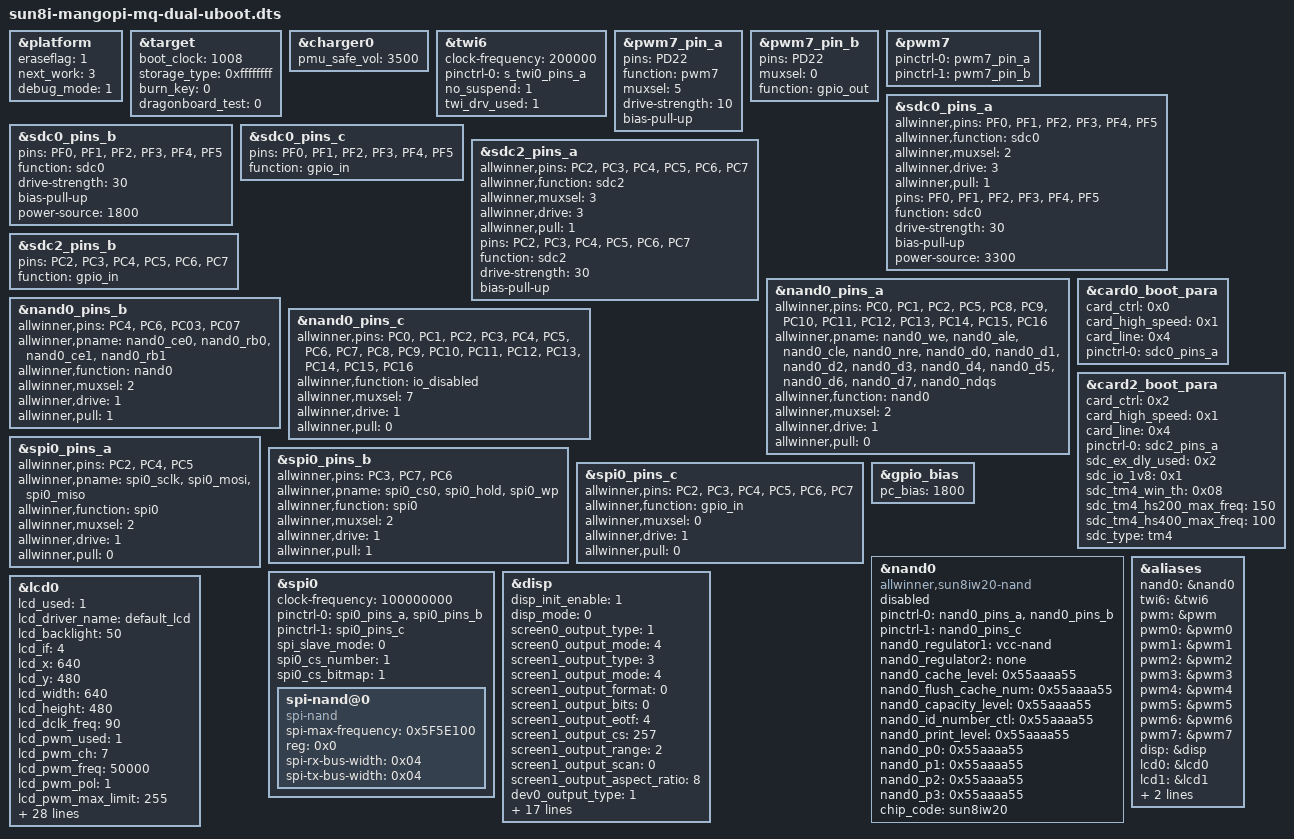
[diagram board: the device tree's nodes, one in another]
/*
 * Allwinner Technology CO., Ltd. sun8iw20p1 soc board.
 *
 * soc board support.
 */
/dts-v1/;

#include "sun8iw20p1-soc-system.dtsi"

&platform {
	eraseflag   = <1>;
	next_work   = <3>;
	debug_mode  = <1>;
};

&target {
	boot_clock = <1008>;	/*CPU boot frequency, Unit: MHz*/
	storage_type = <0xffffffff>; /*boot medium, 0-nand, 1-card0, 2-card2, -1(defualt)auto scan*/
	burn_key = <0>;		/*1:support burn key; 0:not support burn key*/
	dragonboard_test = <0>;	/*1:support card boot dragonboard; 0:not support card boot dragonboard*/
};

&charger0 {
	pmu_safe_vol = <3500>;
};

&twi6 {
	clock-frequency = <200000>;
	pinctrl-0 = <&s_twi0_pins_a>;
	no_suspend = <1>;
	twi_drv_used = <1>;
	status = "okay";
};

&pwm7_pin_a {
	pins = "PD22";
	function = "pwm7";
	muxsel = <5>;
	drive-strength = <10>;
	bias-pull-up;
};

&pwm7_pin_b {
	pins = "PD22";
	muxsel = <0>;
	function = "gpio_out";
};

&pwm7 {
	pinctrl-names = "active", "sleep";
	pinctrl-0 = <&pwm7_pin_a>;
	pinctrl-1 = <&pwm7_pin_b>;
	status = "okay";
};

&sdc0_pins_a {
	allwinner,pins = "PF0", "PF1", "PF2",
			 "PF3", "PF4", "PF5";
	allwinner,function = "sdc0";
	allwinner,muxsel = <2>;
	allwinner,drive = <3>;
	allwinner,pull = <1>;
	pins = "PF0", "PF1", "PF2",
	       "PF3", "PF4", "PF5";
	function = "sdc0";
	drive-strength = <30>;
	bias-pull-up;
	power-source = <3300>;
};

&sdc0_pins_b {
	pins = "PF0", "PF1", "PF2",
	       "PF3", "PF4", "PF5";
	function = "sdc0";
	drive-strength = <30>;
	bias-pull-up;
	power-source = <1800>;
};

&sdc0_pins_c {
		pins = "PF0", "PF1", "PF2",
			"PF3", "PF4", "PF5";
		function = "gpio_in";
};

&sdc2_pins_a {
	allwinner,pins = "PC2", "PC3", "PC4",
			 "PC5", "PC6", "PC7";
	allwinner,function = "sdc2";
	allwinner,muxsel = <3>;
	allwinner,drive = <3>;
	allwinner,pull = <1>;
	pins = "PC2", "PC3", "PC4",
		"PC5", "PC6", "PC7";
	function = "sdc2";
	drive-strength = <30>;
	bias-pull-up;

};

&sdc2_pins_b {
	pins = "PC2", "PC3", "PC4",
	       "PC5", "PC6", "PC7";
	function = "gpio_in";
};

&nand0_pins_a {
	allwinner,pins = "PC0", "PC1", "PC2", "PC5",
			 "PC8", "PC9", "PC10", "PC11",
			 "PC12", "PC13", "PC14", "PC15",
			 "PC16";
	allwinner,pname= "nand0_we", "nand0_ale","nand0_cle", "nand0_nre",
			 "nand0_d0", "nand0_d1", "nand0_d2", "nand0_d3",
			 "nand0_d4", "nand0_d5", "nand0_d6", "nand0_d7",
			 "nand0_ndqs";
	allwinner,function = "nand0";
	allwinner,muxsel = <2>;
	allwinner,drive = <1>;
	allwinner,pull = <0>;
};

&nand0_pins_b {
	allwinner,pins = "PC4", "PC6", "PC03", "PC07";
	allwinner,pname= "nand0_ce0", "nand0_rb0", "nand0_ce1", "nand0_rb1";
	allwinner,function = "nand0";
	allwinner,muxsel = <2>;
	allwinner,drive = <1>;
	allwinner,pull = <1>;	/* only RB&CE should be pulled up */
};

&nand0_pins_c {
	allwinner,pins = "PC0", "PC1", "PC2", "PC3",
			 "PC4", "PC5", "PC6", "PC7",
			 "PC8", "PC9", "PC10", "PC11",
			 "PC12", "PC13", "PC14", "PC15",
			 "PC16";
	allwinner,function = "io_disabled";
	allwinner,muxsel = <7>;
	allwinner,drive = <1>;
	allwinner,pull = <0>;
};

&spi0_pins_a {
	allwinner,pins = "PC2", "PC4", "PC5";
	allwinner,pname = "spi0_sclk", "spi0_mosi", "spi0_miso";
	allwinner,function = "spi0";
	allwinner,muxsel = <2>;
	allwinner,drive = <1>;
	allwinner,pull = <0>;
};

&spi0_pins_b {
	allwinner,pins = "PC3", "PC7", "PC6";
	allwinner,pname = "spi0_cs0", "spi0_hold", "spi0_wp";
	allwinner,function = "spi0";
	allwinner,muxsel = <2>;
	allwinner,drive = <1>;
	allwinner,pull = <1>;   // only CS should be pulled up
};

&spi0_pins_c {
	allwinner,pins = "PC2", "PC3", "PC4", "PC5",
			"PC6", "PC7";
	allwinner,function = "gpio_in";
	allwinner,muxsel = <0>;
	allwinner,drive = <1>;
	allwinner,pull = <0>;
};

&card0_boot_para {  /* Avoid dtc compiling warnings. @TODO: Developer should modify this to the actual value */
	/* reg = <0x0 0x2 0x0 0x0>;  [> Avoid dtc compiling warnings. @TODO: Developer should modify this to the actual value <] */
	device_type = "card0_boot_para";
	card_ctrl = <0x0>;
	card_high_speed = <0x1>;
	card_line = <0x4>;
	pinctrl-0 = <&sdc0_pins_a>;
};

&card2_boot_para {  /* Avoid dtc compiling warnings. @TODO: Developer should modify this to the actual value */
	/* reg = <0x0 0x3 0x0 0x0>;  [> Avoid dtc compiling warnings. @TODO: Developer should modify this to the actual value <] */
	device_type = "card2_boot_para";
	card_ctrl = <0x2>;
	card_high_speed = <0x1>;
	card_line = <0x4>;
	pinctrl-0 = <&sdc2_pins_a>;
	sdc_ex_dly_used = <0x2>;
	sdc_io_1v8 = <0x1>;
	sdc_tm4_win_th = <0x08>;
	sdc_tm4_hs200_max_freq = <150>;
	sdc_tm4_hs400_max_freq = <100>;
	sdc_type = "tm4";
};
&gpio_bias {  /* Avoid dtc compiling warnings. @TODO: Developer should modify this to the actual value */
	device_type = "gpio_bias";
	pc_bias = <1800>;
};

&nand0 {
	compatible = "allwinner,sun8iw20-nand";
	device_type = "nand0";
	//reg = <0x0 0x04011000 0x0 0x1000>;/* nand0 */
	pinctrl-names = "default", "sleep";
	pinctrl-0 = <&nand0_pins_a &nand0_pins_b>;
	pinctrl-1 = <&nand0_pins_c>;
	nand0_regulator1 = "vcc-nand";
	nand0_regulator2 = "none";
	nand0_cache_level = <0x55aaaa55>;
	nand0_flush_cache_num = <0x55aaaa55>;
	nand0_capacity_level = <0x55aaaa55>;
	nand0_id_number_ctl = <0x55aaaa55>;
	nand0_print_level = <0x55aaaa55>;
	nand0_p0 = <0x55aaaa55>;
	nand0_p1 = <0x55aaaa55>;
	nand0_p2 = <0x55aaaa55>;
	nand0_p3 = <0x55aaaa55>;
	chip_code = "sun8iw20";
	status = "disabled";
};

&spi0 {
	clock-frequency = <100000000>;
	pinctrl-0 = <&spi0_pins_a &spi0_pins_b>;
	pinctrl-1 = <&spi0_pins_c>;
	pinctrl-names = "default", "sleep";
	/*spi-supply = <&reg_dcdc1>;*/
	spi_slave_mode = <0>;
	spi0_cs_number = <1>;
	spi0_cs_bitmap = <1>;
	status = "okay";

	spi-nand@0 {
		compatible = "spi-nand";
		spi-max-frequency=<0x5F5E100>;
		reg = <0x0>;
		spi-rx-bus-width=<0x04>;
		spi-tx-bus-width=<0x04>;
		status="okay";
	};
};

&disp {
	disp_init_enable         = <1>;
	disp_mode                = <0>;

	screen0_output_type      = <1>;
	screen0_output_mode      = <4>;

	screen1_output_type      = <3>;
	screen1_output_mode      = <4>;
	
	screen1_output_format    = <0>;
	screen1_output_bits      = <0>;
	screen1_output_eotf      = <4>;
	screen1_output_cs        = <257>;
	screen1_output_range     = <2>;
	screen1_output_scan      = <0>;
	screen1_output_aspect_ratio = <8>;
	dev0_output_type         = <1>;
	dev0_output_mode         = <4>;
	dev0_screen_id           = <0>;
	dev0_do_hpd              = <0>;

	dev1_output_type         = <4>;
	dev1_output_mode         = <10>;
	dev1_screen_id           = <1>;
	dev1_do_hpd              = <1>;

	def_output_dev           = <0>;
	disp_rotation_used		 = <1>;
	degree0					 = <0>;
	fb0_format               = <10>;
	fb0_buffer_num           = <2>;	
	//fb0_width                = <0>;
	//fb0_height               = <0>;
	fb1_format               = <10>;
	fb1_width                = <0>;
	fb1_height               = <0>;
	chn_cfg_mode             = <1>;

	disp_para_zone           = <1>;
	/*VCC-LCD*/
/*	dc1sw-supply = <&reg_dc1sw>;*/
	/*VCC-DSI*/
/*	eldo3-supply = <&reg_eldo3>;*/
	/*VCC-PD*/
/*	dcdc1-supply = <&reg_dcdc1>;*/
}; 

/*
&lcd0 {
	lcd_used            = <1>;					// 启用lcd		

	lcd_driver_name     = "default_lcd";		// 使用 default_lcd 驱动
	lcd_backlight       = <50>;
	lcd_if              = <0>;					// 0:rgb 4:dsi

	lcd_x               = <480>;				// 宽度
	lcd_y               = <320>;				// 高度
	lcd_width           = <480>;				// 屏幕物理宽度，单位 mm
	lcd_height          = <320>;					// 屏幕物理高度，单位 mm
	lcd_dclk_freq       = <49>;					// 屏幕时钟，单位 MHz

	lcd_pwm_used        = <1>;					// 启用背光 PW
	lcd_pwm_ch          = <7>;					// 使用 PWM 通道 7
	lcd_pwm_freq        = <50000>;				// PWM 频率，单位 Hz
	lcd_pwm_pol         = <1>;					// 背光 PWM 的极性	
	//lcd_pwm_max_limit   = <255>;          	// 背光 PWM 的最大值（<=255）

	lcd_hbp             = <2>;					// hsync back porch(pixel) + hsync plus width(pixel);
	lcd_ht              = <486>;				// hsync total cycle(pixel)
	lcd_hspw            = <2>;					// hsync plus width(pixel)	
	lcd_vbp             = <20>;					// vsync back porch(line) + vysnc plus width(line)
	lcd_vt              = <342>;				// vsync total cycle(line)
	lcd_vspw            = <2>;					// vsync plus width(pixel)

	lcd_lvds_if         = <0>;	//LVDS通道数：0是单通道；1是双通道
	lcd_lvds_colordepth = <1>;	//LVDS位宽：0是8位；1是6位
	lcd_lvds_mode       = <0>;	//LVDS模式：0是NS模式；1是JEIDA模式
	lcd_frm             = <0>;					// 0:关闭; 1:启用rgb666抖动; 2:启用rgb656抖动
	lcd_io_phase        = <0x0000>;
	lcd_gamma_en        = <0>;
	lcd_bright_curve_en = <0>;
	lcd_cmap_en         = <0>;

	deu_mode            = <0>;
	lcdgamma4iep        = <22>;
	smart_color         = <90>;

	pinctrl-0 = <&rgb18_pins_a>;
	pinctrl-1 = <&rgb18_pins_b>;	
};
*/

&lcd0 {
	lcd_used            = <1>;

	lcd_driver_name     = "default_lcd";
	lcd_backlight       = <50>;
	lcd_if              = <4>;	//2:ttl; 3:lvds; 4:dsi

	lcd_x               = <640>;
	lcd_y               = <480>;
	lcd_width           = <640>;
	lcd_height          = <480>;
	lcd_dclk_freq       = <90>;

	lcd_pwm_used        = <1>;
	lcd_pwm_ch          = <7>;
	lcd_pwm_freq        = <50000>;
	lcd_pwm_pol         = <1>;
	lcd_pwm_max_limit   = <255>;

	lcd_hbp             = <220>;	//是有效行间，指行同步信号hsync开始到有效数据间的dclk的cyccle个数，包含行同步信号区；即lcd_hbp等于实际hbp+实际
	lcd_ht              = <1084>;	//DCLK的cycle个数，等于lcd_x+lcd_hspw+lcd_hbp+lcd_hfp；驱动会自动根据这个值计算lcd_hfp
	lcd_hspw            = <4>;		//是行同步信号的宽度。即1个data cycle的时间
	lcd_vbp             = <70>;		//场同步信号sync开始到有效数据间的行数，包括场同步信号区；即lcd_vbp等于实际vbp+实际vspw
	lcd_vt              = <624>;	//场的总行数，等于lcd_y+lcd_vspw+lcd_vbp+lcd_vfp；驱动会自动根据这个值计算lcd_vfp
	lcd_vspw            = <2>;		//场同步信号的宽度

	lcd_dsi_if          = <0>;		//mipi-DSI的类型：0是video mode（即：实时刷屏）；1是command mode（即：屏幕有个te引脚）
	lcd_dsi_lane        = <4>;
	lcd_lvds_if         = <0>;
	lcd_lvds_colordepth = <0>;
	lcd_lvds_mode       = <0>;
	lcd_frm             = <0>;		//LCD的色深，0是RGB888；1是RGB666；2是RGB565
	lcd_hv_clk_phase    = <0>;
	lcd_hv_sync_polarity= <0>;
	//lcd_dsi_format      = <0>;		//mipi-DSI的数据格式：0是24bit RGB；1是loosely的18bit RGB；2是18bit RGB；3是16bit RGB
	//lcd_dsi_te          = <0>;		//mipi-DSI的刷屏间隔：0的刷屏间隔是lcd_ht*lcd_vt；1或2的刷屏间隔是2个te脉冲；0是自动；1是上升沿；2是下降沿
	lcd_io_phase        = <0x0000>;
	lcd_gamma_en        = <0>;		//伽马参数：0是关闭；1是开启；设置1后需要对屏驱动中的lcd_gamma_tbl[256]赋值
	lcd_bright_curve_en = <0>;
	lcd_cmap_en         = <0>;		//色彩映射功能：0是关闭；1是开启；设置1后需要对lcd_cmap_tbl[2][3][4]进行赋值
	lcd_fsync_en        = <0>;
	lcd_fsync_act_time  = <1000>;
	lcd_fsync_dis_time  = <1000>;
	lcd_fsync_pol       = <0>;	

	deu_mode            = <0>;
	lcdgamma4iep        = <22>;
	smart_color         = <90>;

	lcd_gpio_0 = <&pio PE 11 GPIO_ACTIVE_HIGH>;
	pinctrl-0 = <&dsi4lane_pins_a>;
	pinctrl-1 = <&dsi4lane_pins_b>;
};

&aliases {
	nand0 = &nand0;
	twi6 = &twi6;
	pwm = &pwm;
	pwm0 = &pwm0;
	pwm1 = &pwm1;
	pwm2 = &pwm2;
	pwm3 = &pwm3;
	pwm4 = &pwm4;
	pwm5 = &pwm5;
	pwm6 = &pwm6;
	pwm7 = &pwm7;
	disp = &disp;
	lcd0 = &lcd0;
	lcd1 = &lcd1;
	eink = &eink;
	spi0 = &spi0;
};
